# M461 register map
File version: 2.0.2.2
Registers are 32-bit, read-write, reset 0x0 unless marked. A register's access mark holds for its fields unless they carry their own. Offsets are from the block's base; [hi:lo] are bit positions; {n}, {i} and the like mark numbered series.

## I2C0 — I2C Bus Interface (I2C)
Base 0x400A0000
Same registers: I2C1 0x400A1000, I2C2 0x400A2000, I2C3 0x400A3000, I2C4 0x400A4000
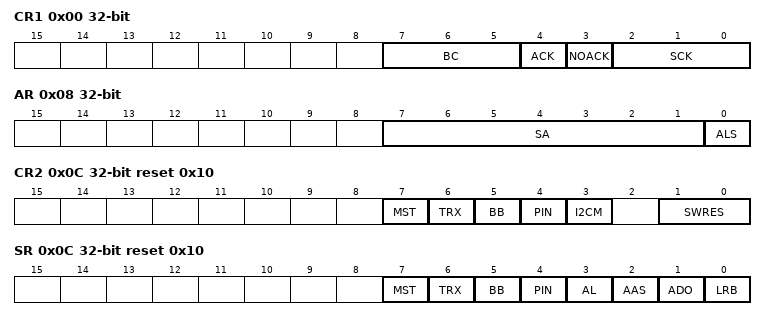
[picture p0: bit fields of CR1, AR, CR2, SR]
0x00 CR1 — I2C Control Register 1
  [7:5] BC, [4] ACK, [3] NOACK ro, [2:0] SCK
0x04 DBR — Data Buffer Register
  [7:0] DB
0x08 AR — Bus address Register
  [7:1] SA, [0] ALS
0x0C CR2 wo reset 0x10 — Control Register 1
  [7] MST, [6] TRX, [5] BB, [4] PIN, [3] I2CM, [1:0] SWRES
0x0C SR ro reset 0x10 — Status Register
  [7] MST, [6] TRX, [5] BB, [4] PIN, [3] AL, [2] AAS, [1] ADO, [0] LRB
0x10 PRS — Prescaler clcok setting Register
  [4:0] PRSCK
0x14 IE — Interrupt Enable Register
  [0] IE
0x18 IR — Interrupt Register
  [0] ISIC

## TB0 — 16-bit Timer_Event Counter (TB)
Base 0x400C4000
Same registers: TB1 0x400C4100, TB2 0x400C4200, TB3 0x400C4300, TB4 0x400C4400, TB5 0x400C4500, TB6 0x400C4600, TB7 0x400C4700, TB8 0x401C4800, TB9 0x401C4900, TBA 0x401C4A00, TBB 0x401C4B00, TBC 0x401C4C00, TBD 0x401C4D00, TBE 0x401C4E00, TBF 0x401C4F00
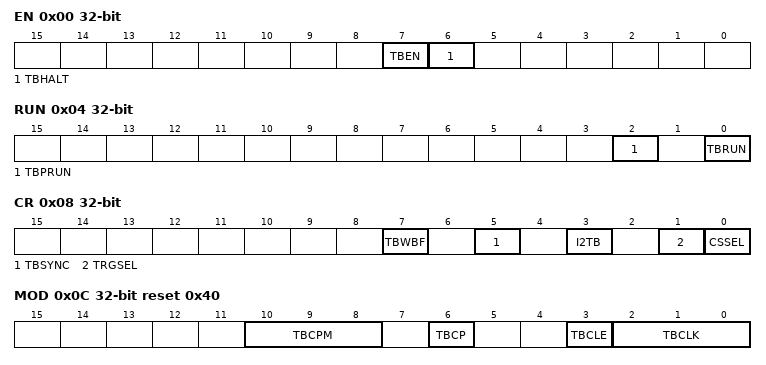
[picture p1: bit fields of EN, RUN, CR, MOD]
0x00 EN — TB Enable Register
  [7] TBEN, [6] TBHALT
0x04 RUN — TB RUN Register
  [2] TBPRUN, [0] TBRUN
0x08 CR — TB Control Register
  [7] TBWBF, [5] TBSYNC, [3] I2TB, [1] TRGSEL, [0] CSSEL
0x0C MOD reset 0x40 — TB Mode Register
  [10:8] TBCPM, [6] TBCP wo, [3] TBCLE, [2:0] TBCLK
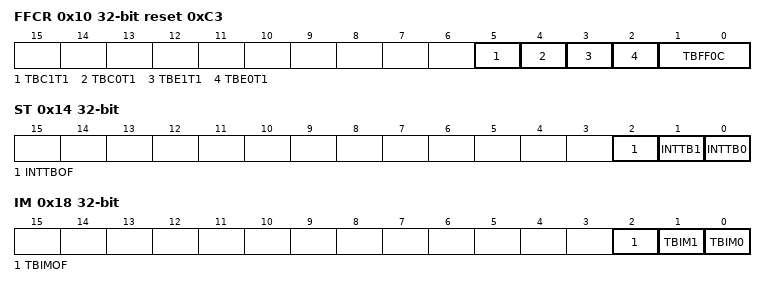
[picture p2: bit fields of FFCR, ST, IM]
0x10 FFCR reset 0xC3 — TB Flip-Flop Control Register
  [5] TBC1T1, [4] TBC0T1, [3] TBE1T1, [2] TBE0T1, [1:0] TBFF0C
0x14 ST ro — TB Status Register
  [2] INTTBOF, [1] INTTB1, [0] INTTB0
0x18 IM — TB Interrupt Mask Register
  [2] TBIMOF, [1] TBIM1, [0] TBIM0
0x1C UC ro — TB Read Capture Register
  [15:0] TBUC
0x20 RG0 — TB RG0 Timer Register
  [15:0] TBRG0
0x24 RG1 — TB RG1 Timer Register
  [15:0] TBRG1
0x28 CP0 ro (reset mask 0xFFFF0000) — TB CP0 Capture Register
  [15:0] TBCP0
0x2C CP1 ro (reset mask 0xFFFF0000) — TB CP1 Capture Register
  [15:0] TBCP1

## SC0 — Serial Channel (SC)
Base 0x400E1000
Same registers: SC1 0x400E1100, SC2 0x400E1200, SC3 0x401E1300, SC4 0x401E1400, SC5 0x401E1500
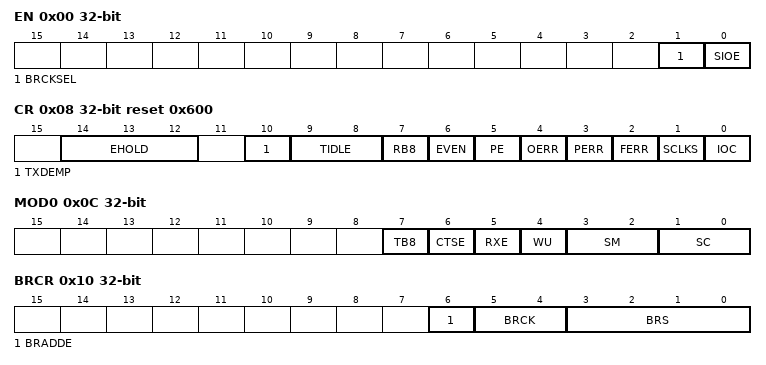
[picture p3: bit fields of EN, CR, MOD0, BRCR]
0x00 EN — SC Enable Register
  [1] BRCKSEL, [0] SIOE
0x04 BUF — SC Buffer Register
  [7:0] TB_RB
0x08 CR reset 0x600 — SC Control Register
  [14:12] EHOLD, [10] TXDEMP, [9:8] TIDLE, [7] RB8 ro, [6] EVEN, [5] PE, [4] OERR ro, [3] PERR ro, [2] FERR ro, [1] SCLKS, [0] IOC
0x0C MOD0 — SC Mode Control Register 0
  [7] TB8, [6] CTSE, [5] RXE, [4] WU, [3:2] SM, [1:0] SC
0x10 BRCR — SC Baud Rate Generator Control Register
  [6] BRADDE, [5:4] BRCK, [3:0] BRS
0x14 BRADD — SC Baud Rate Generator Control Register 2
  [3:0] BRK
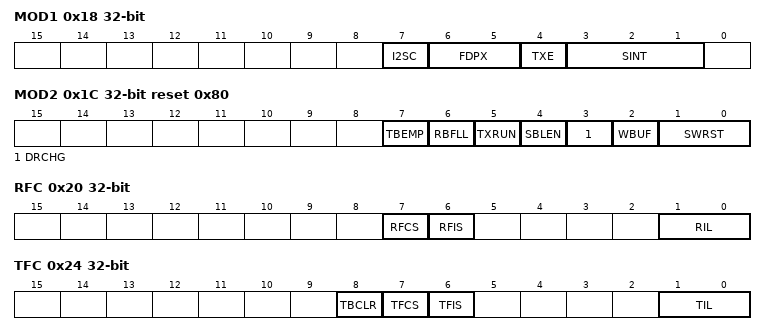
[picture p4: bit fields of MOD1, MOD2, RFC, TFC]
0x18 MOD1 — SC Mode Control Register 1
  [7] I2SC, [6:5] FDPX, [4] TXE, [3:1] SINT
0x1C MOD2 reset 0x80 — SC Mode Control Register 2
  [7] TBEMP ro, [6] RBFLL ro, [5] TXRUN ro, [4] SBLEN, [3] DRCHG, [2] WBUF, [1:0] SWRST
0x20 RFC — SC RX FIFO Configuration Register
  [7] RFCS wo, [6] RFIS, [1:0] RIL
0x24 TFC — SC TX FIFO Configuration Register
  [8] TBCLR wo, [7] TFCS wo, [6] TFIS, [1:0] TIL
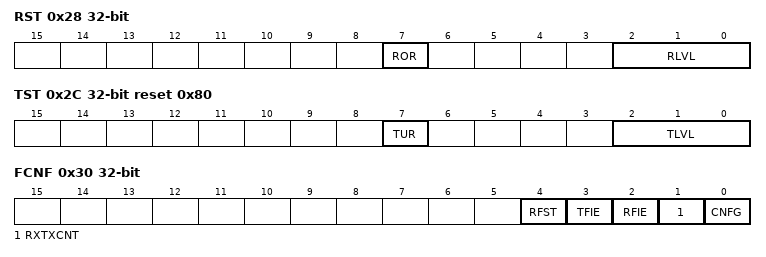
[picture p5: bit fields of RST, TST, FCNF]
0x28 RST ro — SC RX FIFO Status Register
  [7] ROR, [2:0] RLVL
0x2C TST ro reset 0x80 — SC TX FIFO Status Register
  [7] TUR, [2:0] TLVL
0x30 FCNF — SC FIFO Configuration Register
  [4] RFST, [3] TFIE, [2] RFIE, [1] RXTXCNT, [0] CNFG

## PA — Port A
Base 0x402C0000
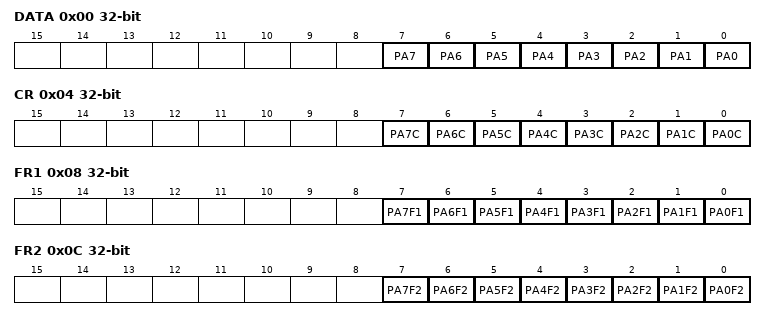
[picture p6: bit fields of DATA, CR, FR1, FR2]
0x00 DATA — Port A Data Register
  [n] PA{n} (n=0..7)
0x04 CR — Port A Output Control Register
  [n] PA{n}C (n=0..7)
0x08 FR1 — Port A Function Register 1
  [n] PA{n}F1 (n=0..7)
0x0C FR2 — Port A Function Register 2
  [n] PA{n}F2 (n=0..7)
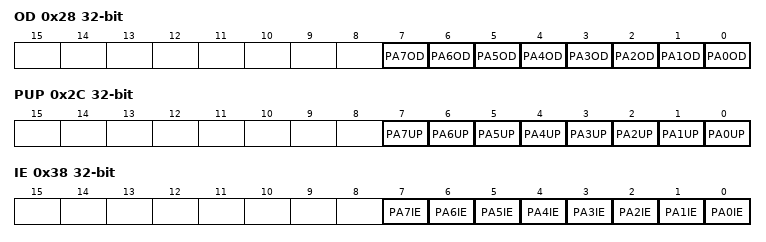
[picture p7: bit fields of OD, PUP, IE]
0x28 OD — Port A Open Drain Control Register
  [n] PA{n}OD (n=0..7)
0x2C PUP — Port A Pull-up Control Register
  [n] PA{n}UP (n=0..7)
0x38 IE — Port A Input Control Register
  [n] PA{n}IE (n=0..7)

## PB — Port B
Base 0x402C0100
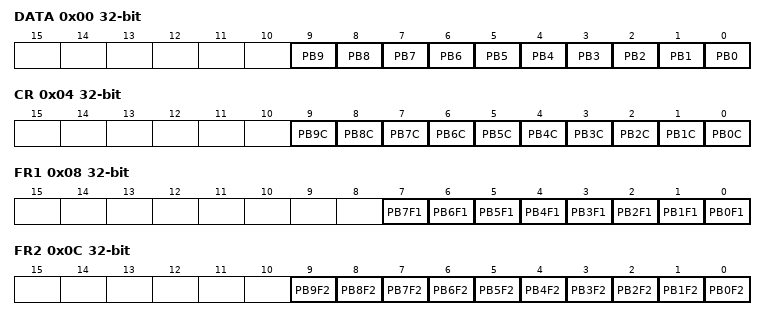
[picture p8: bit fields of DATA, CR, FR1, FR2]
0x00 DATA — Port B Data Register
  [n] PB{n} (n=0..9)
0x04 CR — Port B Output Control Register
  [n] PB{n}C (n=0..9)
0x08 FR1 — Port B Function Register 1
  [n] PB{n}F1 (n=0..7)
0x0C FR2 — Port B Function Register 2
  [n] PB{n}F2 (n=0..9)
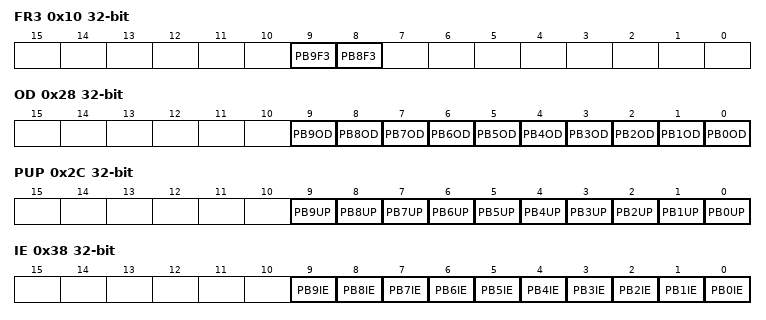
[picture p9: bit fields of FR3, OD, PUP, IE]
0x10 FR3 — Port B Function Register 3
  [9] PB9F3, [8] PB8F3
0x28 OD — Port B Open Drain Control Register
  [n] PB{n}OD (n=0..9)
0x2C PUP — Port B Pull-up Control Register
  [n] PB{n}UP (n=0..9)
0x38 IE — Port B Input Control Register
  [n] PB{n}IE (n=0..9)
